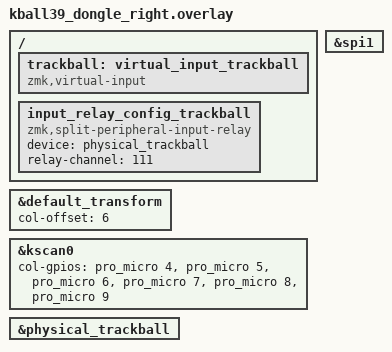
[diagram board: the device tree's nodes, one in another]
/* Dongle mode: right half relays its physical trackball to the receiver. */

#include "../keyball_nano/keyball39.dtsi"
#define trackball physical_trackball
#include "../keyball_nano/keyball39_pmw3610.dtsi"
#undef trackball

&default_transform {
    col-offset = <6>;
};

&kscan0 {
    col-gpios
        = <&pro_micro 4 GPIO_ACTIVE_HIGH>
        , <&pro_micro 5 GPIO_ACTIVE_HIGH>
        , <&pro_micro 6 GPIO_ACTIVE_HIGH>
        , <&pro_micro 7 GPIO_ACTIVE_HIGH>
        , <&pro_micro 8 GPIO_ACTIVE_HIGH>
        , <&pro_micro 9 GPIO_ACTIVE_HIGH>
        ;
};

&spi1 {
    status = "okay";
};

&physical_trackball {
    status = "okay";
};

/ {
    trackball: virtual_input_trackball {
        compatible = "zmk,virtual-input";
    };

    input_relay_config_trackball {
        compatible = "zmk,split-peripheral-input-relay";
        device = <&physical_trackball>;
        relay-channel = <111>;
    };
};
